AUTOSAR XML (schema 00049)
package /Application/DltConfig
  dlt log channel to process mapping DltLogChannelToProcessMapping_ServiceCreator_TO_ServiceCreator: dlt-log-channel=ServiceCreator, process=ServiceCreator
package /Application/Executable
  executable ServiceCreator: category=APPLICATION_LEVEL, logging-behavior=DOES-NOT-USE-LOGGING, reporting-behavior=REPORTS-EXECUTION-STATE, version=1.0.0
    root sw component prototype AA: application-type=ServiceCreator
package /Application/Manifest
  5 x service instance to port prototype mapping:
    ServiceCreator_AA_BCM_WiperWash: port-prototype=AA.BCM_WiperWash, service-instance=Provider_BCM_WiperWash
    ServiceCreator_AA_VCS_AccrPedal: port-prototype=AA.VCS_AccrPedal, service-instance=Provider_VCS_AccrPedal
    ServiceCreator_AA_VCS_BrakeSwitch: port-prototype=AA.VCS_BrakeSwitch, service-instance=Provider_VCS_BrakeSwitch
    ServiceCreator_AA_VCS_Gear: port-prototype=AA.VCS_Gear, service-instance=Provider_VCS_Gear
    ServiceCreator_AA_VCS_VehSpd: port-prototype=AA.VCS_VehSpd, service-instance=Provider_VCS_VehSpd
package /Application/Process
  process ServiceCreator: executable=ServiceCreator, state-dependent-startup-config{execution-dependency=CM.Running, function-group-state=MachineFG.Startup, resource-group=DefaultResourceGroup, startup-config=ServiceCreator}
    process state machine ServiceCreator: type=ProcessState
package /Application/StartupConfig
  startup config set EEVP_ServiceCreator_StartupConfig
    startup config ServiceCreator: scheduling-policy=SCHED_OTHER, scheduling-priority=0
package /Application/SwComponent
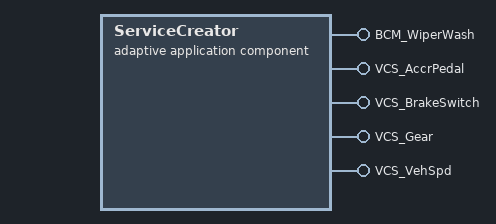
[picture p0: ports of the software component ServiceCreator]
  adaptive application sw component type ServiceCreator
    5 x provide port:
      BCM_WiperWash: provided-interface=BCM_WiperWash
      VCS_AccrPedal: provided-interface=VCS_AccrPedal
      VCS_BrakeSwitch: provided-interface=VCS_BrakeSwitch
      VCS_Gear: provided-interface=VCS_Gear
      VCS_VehSpd: provided-interface=VCS_VehSpd
